# MKW36Z4 register map
Vendor: NXP Semiconductors; Series: Kinetis_W; File version: 1.6
CPU: CM0PLUS r0p0, little endian, no MPU, no FPU, VTOR, 2 interrupt priority bits
Registers are 16-bit, read-write, no defined reset value unless marked. A register's access mark holds for its fields unless they carry their own. Offsets are from the block's base; [hi:lo] are bit positions; {n}, {i} and the like mark numbered series; 'fields as' and 'values as' point back to an identical list.

## MTB — Micro Trace Buffer
Base 0xF0000000; register names take the prefix MTB_
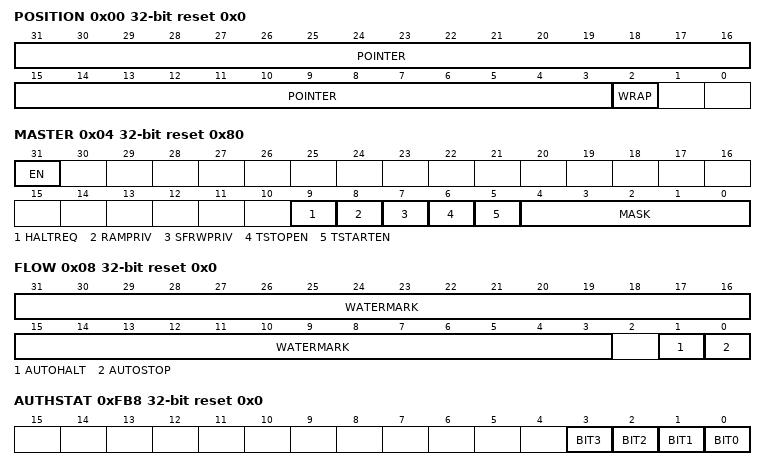
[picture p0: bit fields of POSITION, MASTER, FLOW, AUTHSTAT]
0x00 POSITION 32-bit reset 0x0 (reset mask 0x3) — MTB Position Register
  [31:3] POINTER — Trace Packet Address Pointer[28:0]
  [2] WRAP
0x04 MASTER 32-bit reset 0x80 (reset mask 0xFFFFFFE0) — MTB Master Register
  [31] EN — Main Trace Enable
  [9] HALTREQ — Halt Request
  [8] RAMPRIV — RAM Privilege
  [7] SFRWPRIV — Special Function Register Write Privilege
  [6] TSTOPEN — Trace Stop Input Enable
  [5] TSTARTEN — Trace Start Input Enable
  [4:0] MASK
0x08 FLOW 32-bit reset 0x0 (reset mask 0x4) — MTB Flow Register
  [31:3] WATERMARK — WATERMARK[28:0]
  [1] AUTOHALT
  [0] AUTOSTOP
0x0C BASE 32-bit ro — MTB Base Register
  [31:0] BASEADDR
0xF00 MODECTRL 32-bit ro reset 0x0 — Integration Mode Control Register
0xFA0 TAGSET 32-bit ro reset 0x0 — Claim TAG Set Register
0xFA4 TAGCLEAR 32-bit ro reset 0x0 — Claim TAG Clear Register
0xFB0 LOCKACCESS 32-bit ro reset 0x0
  [31:0] LOCKACCESS — Hardwired to 0x0000_0000
0xFB4 LOCKSTAT 32-bit ro reset 0x0 — Lock Status Register
0xFB8 AUTHSTAT 32-bit ro reset 0x0 — Authentication Status Register
  [3] BIT3
  [2] BIT2
  [1] BIT1
  [0] BIT0 — Connected to DBGEN.
0xFBC DEVICEARCH 32-bit ro reset 0x47700A31 — Device Architecture Register
0xFC8 DEVICECFG 32-bit ro reset 0x0 — Device Configuration Register
0xFCC DEVICETYPID 32-bit ro reset 0x31 — Device Type Identifier Register
0xFD0 PERIPHID{x} (x=4,5,6,7,0,1,2,3; step 0x4) 32-bit ro — Peripheral ID Register
  [31:0] PERIPHID
{0xFF0+4i} COMPID{i} (i=0..3) 32-bit ro — Component ID Register
  [31:0] COMPID — Component ID

## MTBDWT — MTB data watchpoint and trace
Base 0xF0001000; register names take the prefix MTBDWT_
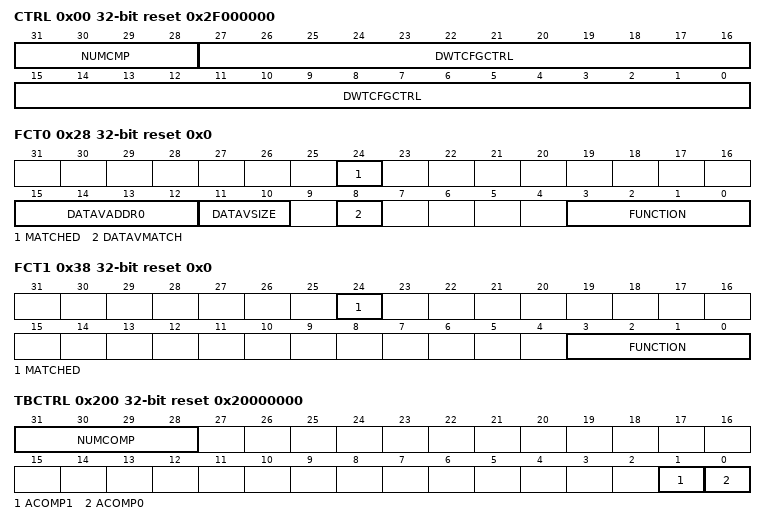
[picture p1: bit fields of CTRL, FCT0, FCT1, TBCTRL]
0x00 CTRL 32-bit ro reset 0x2F000000 — MTB DWT Control Register
  [31:28] NUMCMP — Number of comparators
  [27:0] DWTCFGCTRL — DWT configuration controls
{0x20+0x10*i} COMP{i} (i=0..1) 32-bit reset 0x0 — MTB_DWT Comparator Register
  [31:0] COMP — Reference value for comparison
{0x24+0x10*i} MASK{i} (i=0..1) 32-bit reset 0x0 — MTB_DWT Comparator Mask Register
  [4:0] MASK
0x28 FCT0 32-bit reset 0x0 — MTB_DWT Comparator Function Register 0
  [24] MATCHED ro — Comparator match
    0=No match; 1=Match occurred
  [15:12] DATAVADDR0 — Data Value Address 0
  [11:10] DATAVSIZE — Data Value Size
    0=Byte; 1=Halfword; 2=Word; 3=Reserved. Any attempts to use this value results in UNPREDICTABLE behavior.
  [8] DATAVMATCH — Data Value Match
    0=Perform address comparison; 1=Perform data value comparison
  [3:0] FUNCTION
    0=Disabled; 4=Instruction fetch; 5=Data operand read; 6=Data operand write; 7=Data operand (read + write)
0x38 FCT1 32-bit reset 0x0 — MTB_DWT Comparator Function Register 1
  [24] MATCHED ro — Comparator match
    0=No match; 1=Match occurred
  [3:0] FUNCTION
    values as FCT0.FUNCTION
0x200 TBCTRL 32-bit reset 0x20000000 — MTB_DWT Trace Buffer Control Register
  [31:28] NUMCOMP ro — Number of Comparators
  [1] ACOMP1 — Action based on Comparator 1 match
    0=Trigger TSTOP based on the assertion of MTBDWT_FCT1[MATCHED]; 1=Trigger TSTART based on the assertion of MTBDWT_FCT1[MATCHED]
  [0] ACOMP0 — Action based on Comparator 0 match
    0=Trigger TSTOP based on the assertion of MTBDWT_FCT0[MATCHED]; 1=Trigger TSTART based on the assertion of MTBDWT_FCT0[MATCHED]
0xFC8 DEVICECFG 32-bit ro reset 0x0 — Device Configuration Register
0xFCC DEVICETYPID 32-bit ro reset 0x4 — Device Type Identifier Register
0xFD0 PERIPHID{x} (x=4,5,6,7,0,1,2,3; step 0x4) 32-bit ro — Peripheral ID Register
  [31:0] PERIPHID
{0xFF0+4i} COMPID{i} (i=0..3) 32-bit ro — Component ID Register
  [31:0] COMPID — Component ID
